# aes: IP-XACT component
VLNV lowrisc.org:opentitan:aes:0.1

## Parameters
NumRegsKey = 8
EN_MASKING = 1

## Bus interfaces (logical=physical port)
tlul: slave lowrisc.org:ip:tlul:1.0, memory map aes_regs
  a_valid=tl_i_a_valid, a_ready=tl_o_a_ready, d_valid=tl_o_d_valid, d_ready=tl_i_d_ready
edn: master lowrisc.org:ip:edn:1.0, address space edn_addr_space

## Ports
in clk_i
in rst_ni
in rst_shadowed_ni
in clk_edn_i
in rst_edn_ni
out idle_o
in lc_escalate_en_i
out edn_o
in edn_i
in keymgr_key_i
in tl_i
out tl_o
in alert_rx_i[NumAlerts-1:0]
out alert_tx_o[NumAlerts-1:0]

## Address spaces and blocks
edn_addr_space: range 0x1000, width 32
aes_regs.regs: base 0x0, range 0x100, width 32

## Registers
Registers are 32-bit, read-write, reset 0x1 unless marked. A register's access mark holds for its fields unless they carry their own. Offsets are from the block's base; lines under a group give offsets from that group; [hi:lo] are bit positions; {n}, {i} and the like mark numbered series; 'fields as' and 'values as' point back to an identical list; <NAME> marks a mode.

## aes_regs.regs
Base 0x00000000
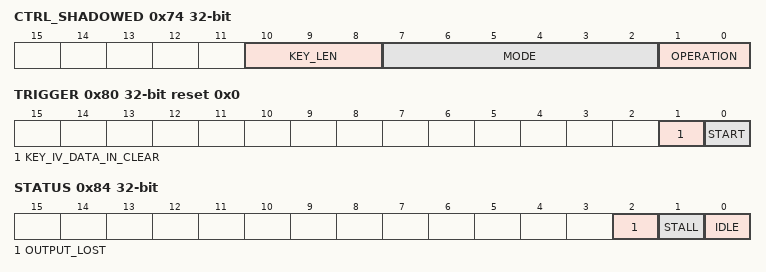
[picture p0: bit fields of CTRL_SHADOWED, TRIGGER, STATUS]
0x74 CTRL_SHADOWED
  [10:8] KEY_LEN
  [7:2] MODE
  [1:0] OPERATION
    1=AES_ENC; 2=AES_DEC; 3=AES_NONE
0x80 TRIGGER wo reset 0x0
  [1] KEY_IV_DATA_IN_CLEAR, [0] START
0x84 STATUS ro reset not defined
  [2] OUTPUT_LOST, [1] STALL, [0] IDLE
